# A34L71x register map
Vendor: ABOV Semiconductor Co., Ltd.; File version: 1.0
CPU: CM4 r0p1, little endian, MPU, FPU, VTOR, 4 interrupt priority bits
Registers are 32-bit, read-write, reset 0x0 unless marked. A register's access mark holds for its fields unless they carry their own. Offsets are from the block's base; [hi:lo] are bit positions; {n}, {i} and the like mark numbered series; <NAME> marks a mode.

## HSICMU — HIGH-SPEED INTERNAL OSC CLOCK MANAGEMENT UNIT
Base 0x40004000
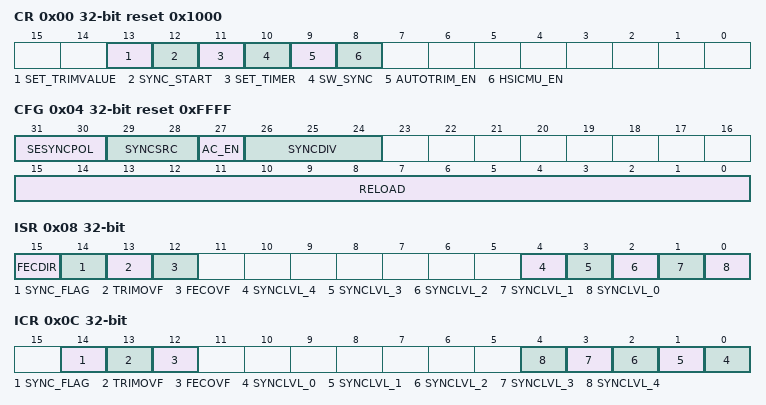
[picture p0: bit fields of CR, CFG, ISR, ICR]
0x00 CR reset 0x1000 — High Speed Internal OSC Clock Management Unit Control Register
  [13] SET_TRIMVALUE — The value of the trim register is applied to the high speed internal OSC 0: No Action 1: The value of the trim register is applied to the high speed internal OSC
  [12] SYNC_START — Start synchronized timer 0: No Action 1: Start synchronized timer
  [11] SET_TIMER — The value in the Reload register is written to the FERRCNT 0: No Action 1: The value in the Reload register is written to the Frequency Error Rate Counter
  [10] SW_SYNC — Generate Software SYNC event 0: No Action 1: A software SYNC event is generate
  [9] AUTOTRIM_EN — Auto Trim Enable 0: Auto trimming disable 1: Auto trimming enable *This bit enables the automatic hardware adjustment of TRIM bits according to the measured frequency error between two SYNC events. If this bit is set, the TRIM bits are read-only. The TRIM value can be adjusted by hardware by one or two ot three steps at a time, depending on the measured frequency error value. ** Before setting this bit, you must load the trim value into the trim register and set SET_TRIMVALUE BIT to 1.
  [8] HSICMU_EN — HSICMU Peripheral block Enable 0: disable 1: enable
0x04 CFG reset 0xFFFF — High Speed Internal OSC Clock Management Unit Config Register
  [31:30] SESYNCPOL — This bit is set and cleared by software to select the input polarity for the SYNC signal source. 00: Both edge. 01: Rising edge. 10: Falling edge. 11: RESERVED.
  [29:28] SYNCSRC — SYNC Signal Source Selection These bits are set and cleared by software to select the SYNC signal source. 00: Capture Data Update when SOF is successfully received. 01: Capture Data Update when SOF is successfully received and also even when SOF is missed. 10: SOSC CLK. 11: GPIO.
  [27] AC_EN — Auto Clear Enable 0: No Action 1: Auto Clear Enable
  [26:24] SYNCDIV — SYNC Divider These bits are set and cleared by software to control the division factor of the SYNC signal. 000: SYNC not divided (default) 001: SYNC divided by 2 010: SYNC divided by 4 011: SYNC divided by 8 100: SYNC divided by 16 101: SYNC divided by 32 110: SYNC divided by 64 111: SYNC divided by 128
  [15:0] RELOAD — Sync Timer Reload Value RELOAD is the value to be loaded in the Synctimer with each SYNC event.
0x08 ISR ro — High Speed Internal OSC Clock Management Unit Interrupt & Status Register
  [15] FECDIR — Frequency Error Capture Direction 0: count under reload 1: count over reload
  [14] SYNC_FLAG — Sync Signal Flag 0: None 1: Updated HSICMU_CAP register with input sync signal
  [13] TRIMOVF — Trim Value Over flow 0: None 1: The trim value is out of limits when AUTOTRIMEN = 1
  [12] FECOVF — Frequency Error Capture Over Flow 0: None 1: The Counter value changed in the increasing direction and the counter value increased to the end (0xFFFF)
  [4] SYNCLVL_4 — FETHR * 128 < HSICMU_CAP
  [3] SYNCLVL_3 — FETHR * 4 < HSICMU_CAP <= FETHR * 128
  [2] SYNCLVL_2 — FETHR * 2 < HSICMU_CAP <= FETHR *4
  [1] SYNCLVL_1 — FETHR < HSICMU_CAP <= FETHR * 2
  [0] SYNCLVL_0 — HSICMU_CAP <= FETHR
0x0C ICR wo — High Speed Internal OSC Clock Management Unit Interrupt & Status Clear Register
  [14] SYNC_FLAG — Sync Signal Flag clear
  [13] TRIMOVF — Trim Value Over flow flag clear
  [12] FECOVF — Frequency Error Over Flow flag clear
  [n] SYNCLVL_{n} (n=0..4)
0x10 TRIM — High Speed Internal OSC Clock Management Unit TRIM Register
  [10:0] TRIM — Trim value register for trimming
0x14 ATRIM ro — High Speed Internal OSC Clock Management Unit Auto TRIM Register
  [10:0] ATRIM — Current trim value during auto trimming
0x18 CAP ro — High Speed Internal OSC Clock Management Unit Capture Register
  [15:0] CAPTURE — Capture value of the frequency error rate counter
0x1C THR — HSICMU Frequency Error rate threshold
  [15:0] FETHR — Frequency Error rate threshold
